VERSION ""

NS_ :

BS_:

BU_: DBG VCU BMS MCM DCU

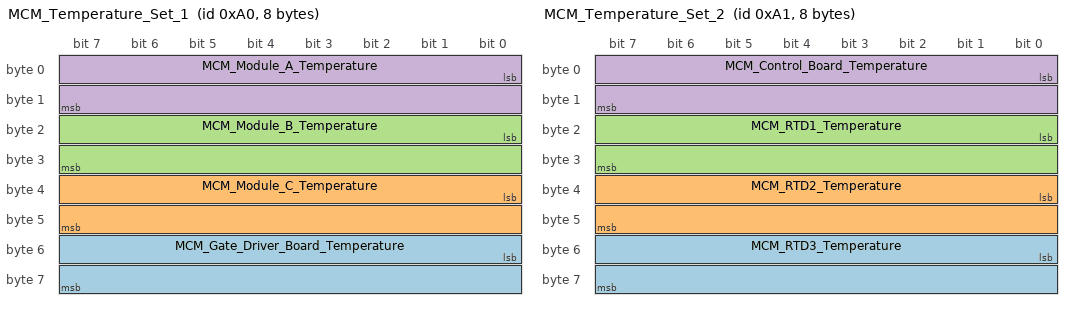
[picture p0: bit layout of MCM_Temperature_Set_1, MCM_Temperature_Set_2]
BO_ 160 MCM_Temperature_Set_1: 8 MCM
 SG_ MCM_Gate_Driver_Board_Temperature : 48|16@1- (0.1,0) [-3276.8|3276.7] "C" VCU
 SG_ MCM_Module_C_Temperature : 32|16@1- (0.1,0) [-3276.8|3276.7] "C" VCU
 SG_ MCM_Module_B_Temperature : 16|16@1- (0.1,0) [-3276.8|3276.7] "C" VCU
 SG_ MCM_Module_A_Temperature : 0|16@1- (0.1,0) [-3276.8|3276.7] "C" VCU

BO_ 161 MCM_Temperature_Set_2: 8 MCM
 SG_ MCM_RTD3_Temperature : 48|16@1- (0.1,0) [-3276.8|3276.7] "C" VCU
 SG_ MCM_RTD2_Temperature : 32|16@1- (0.1,0) [-3276.8|3276.7] "C" VCU
 SG_ MCM_RTD1_Temperature : 16|16@1- (0.1,0) [-3276.8|3276.7] "C" VCU
 SG_ MCM_Control_Board_Temperature : 0|16@1- (0.1,0) [-3276.8|3276.7] "C" VCU

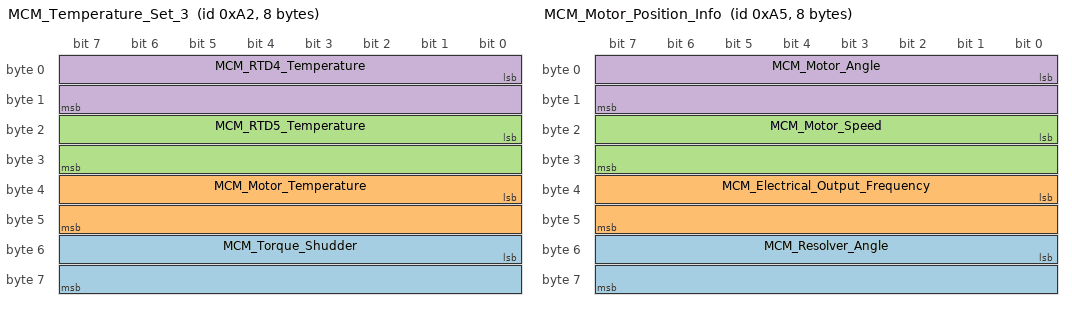
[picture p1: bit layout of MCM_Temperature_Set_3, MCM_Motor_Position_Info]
BO_ 162 MCM_Temperature_Set_3: 8 MCM
 SG_ MCM_Torque_Shudder : 48|16@1- (0.1,0) [-3276.8|3276.7] "Nm" VCU
 SG_ MCM_Motor_Temperature : 32|16@1- (0.1,0) [-3276.8|3276.7] "C" VCU
 SG_ MCM_RTD5_Temperature : 16|16@1- (0.1,0) [-3276.8|3276.7] "C" VCU
 SG_ MCM_RTD4_Temperature : 0|16@1- (0.1,0) [-3276.8|3276.7] "C" VCU

BO_ 165 MCM_Motor_Position_Info: 8 MCM
 SG_ MCM_Resolver_Angle : 48|16@1- (0.1,0) [-3276.8|3276.7] "DEG" VCU
 SG_ MCM_Electrical_Output_Frequency : 32|16@1- (0.1,0) [-3276.8|3276.7] "Hz" VCU
 SG_ MCM_Motor_Speed : 16|16@1- (1,0) [-32768|32767] "RPM" VCU
 SG_ MCM_Motor_Angle : 0|16@1+ (0.1,0) [0|6553.5] "DEG" VCU

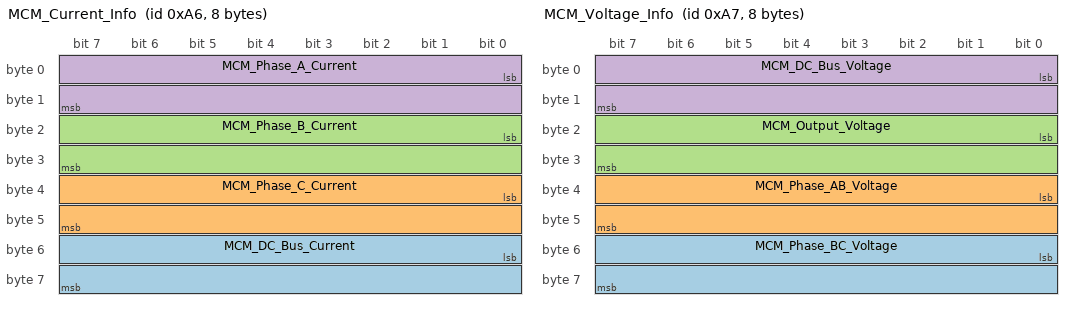
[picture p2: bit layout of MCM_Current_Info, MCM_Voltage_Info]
BO_ 166 MCM_Current_Info: 8 MCM
 SG_ MCM_DC_Bus_Current : 48|16@1- (0.1,0) [-3276.8|3276.7] "A" VCU
 SG_ MCM_Phase_C_Current : 32|16@1- (0.1,0) [-3276.8|3276.7] "A" VCU
 SG_ MCM_Phase_B_Current : 16|16@1- (0.1,0) [-3276.8|3276.7] "A" VCU
 SG_ MCM_Phase_A_Current : 0|16@1- (0.1,0) [-3276.8|3276.7] "A" VCU

BO_ 167 MCM_Voltage_Info: 8 MCM
 SG_ MCM_Phase_BC_Voltage : 48|16@1- (0.1,0) [-3276.8|3276.7] "V" VCU
 SG_ MCM_Phase_AB_Voltage : 32|16@1- (0.1,0) [-3276.8|3276.7] "V" VCU
 SG_ MCM_Output_Voltage : 16|16@1- (0.1,0) [-3276.8|3276.7] "V" VCU
 SG_ MCM_DC_Bus_Voltage : 0|16@1- (0.1,0) [-3276.8|3276.7] "V" VCU

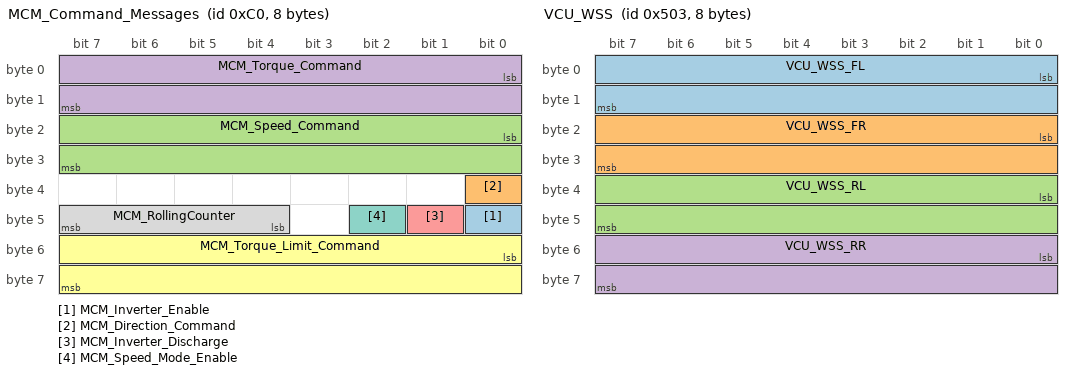
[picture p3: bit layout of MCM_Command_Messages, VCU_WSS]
BO_ 192 MCM_Command_Messages: 8 VCU
 SG_ MCM_Inverter_Enable : 40|1@1+ (1,0) [0|1] "Bit" MCM
 SG_ MCM_Direction_Command : 32|1@1+ (1,0) [0|1] "Bit" MCM
 SG_ MCM_Speed_Command : 16|16@1- (1,0) [-32768|32767] "rpm" MCM
 SG_ MCM_Torque_Command : 0|16@1- (0.1,0) [-3276.8|3276.7] "Nm" MCM
 SG_ MCM_Inverter_Discharge : 41|1@1+ (1,0) [0|1] "Bit" MCM
 SG_ MCM_Torque_Limit_Command : 48|16@1- (0.1,0) [-3276.8|3276.7] "Nm" MCM
 SG_ MCM_Speed_Mode_Enable : 42|1@1+ (1,0) [0|1] "Bit" MCM
 SG_ MCM_RollingCounter : 44|4@1+ (1,0) [0|15] "Bits" MCM

BO_ 1280 VCU_TPS0: 8 VCU
 SG_ VCU_TPS0_Value : 16|16@1+ (0.0946969697,-714) [0|100] "%" VCU

BO_ 1281 VCU_TPS1: 8 VCU
 SG_ VCU_TPS1_Value : 16|16@1+ (0.0916590284,-3563) [0|100] "%" VCU

BO_ 1282 VCU_BPS: 8 VCU
 SG_ VCU_BPS_Percent : 0|16@1+ (1,0) [0|100] "%" VCU
 SG_ VCU_BPS_Value : 16|16@1+ (0.1,0) [0|8000] "PSI" VCU

BO_ 1283 VCU_WSS: 8 VCU
 SG_ VCU_WSS_FL : 0|16@1- (1,0) [-100000|100000] "mm/s" VCU
 SG_ VCU_WSS_FR : 16|16@1- (1,0) [-100000|100000] "mm/s" VCU
 SG_ VCU_WSS_RL : 32|16@1- (1,0) [-100000|100000] "mm/s" VCU
 SG_ VCU_WSS_RR : 48|16@1- (1,0) [-100000|100000] "mm/s" VCU

BO_ 1286 VCU_Safety_Checker: 8 VCU
 SG_ VCU_FAULT_TPS_OutOfRange : 0|1@1+ (1,0) [0|1] "Bit" VCU
 SG_ VCU_FAULT_BPS_OutOfRange : 1|1@1+ (1,0) [0|1] "Bit" VCU
 SG_ VCU_FAULT_TPS_PowerFailure : 2|1@1+ (1,0) [0|1] "Bit" VCU
 SG_ VCU_FAULT_BPS_PowerFailure : 3|1@1+ (1,0) [0|1] "Bit" VCU
 SG_ VCU_FAULT_TPS_SignalFailure : 4|1@1+ (1,0) [0|1] "Bit" VCU
 SG_ VCU_FAULT_BPS_SignalFailure : 5|1@1+ (1,0) [0|1] "Bit" VCU
 SG_ VCU_FAULT_TPS_NotCalibrated : 6|1@1+ (1,0) [0|1] "Bit" VCU
 SG_ VCU_FAULT_BPS_NotCalibrated : 7|1@1+ (1,0) [0|1] "Bit" VCU
 SG_ VCU_FAULT_TPS_OutOfSync : 8|1@1+ (1,0) [0|1] "Bit" VCU
 SG_ VCU_FAULT_BPS_OutOfSync : 9|1@1+ (1,0) [0|1] "Bit" VCU
 SG_ VCU_FAULT_TPSBPS_Implausible : 10|1@1+ (1,0) [0|1] "Bit" VCU
 SG_ VCU_FAULT_UNUSED_11 : 11|1@1+ (1,0) [0|1] "Bit" VCU
 SG_ VCU_FAULT_UNUSED_12 : 12|1@1+ (1,0) [0|1] "Bit" VCU
 SG_ VCU_FAULT_UNUSED_13 : 13|1@1+ (1,0) [0|1] "Bit" VCU
 SG_ VCU_FAULT_UNUSED_14 : 14|1@1+ (1,0) [0|1] "Bit" VCU
 SG_ VCU_FAULT_UNUSED_15 : 15|1@1+ (1,0) [0|1] "Bit" VCU
 SG_ VCU_FAULT_LVS_BatteryVeryLow : 16|1@1+ (1,0) [0|1] "Bit" VCU
 SG_ VCU_FAULT_UNUSED_17 : 17|1@1+ (1,0) [0|1] "Bit" VCU
 SG_ VCU_FAULT_UNUSED_18 : 18|1@1+ (1,0) [0|1] "Bit" VCU
 SG_ VCU_FAULT_UNUSED_19 : 19|1@1+ (1,0) [0|1] "Bit" VCU
 SG_ VCU_FAULT_UNUSED_20 : 20|1@1+ (1,0) [0|1] "Bit" VCU
 SG_ VCU_FAULT_UNUSED_21 : 21|1@1+ (1,0) [0|1] "Bit" VCU
 SG_ VCU_FAULT_UNUSED_22 : 22|1@1+ (1,0) [0|1] "Bit" VCU
 SG_ VCU_FAULT_UNUSED_23 : 23|1@1+ (1,0) [0|1] "Bit" VCU
 SG_ VCU_FAULT_UNUSED_24 : 24|1@1+ (1,0) [0|1] "Bit" VCU
 SG_ VCU_FAULT_UNUSED_25 : 25|1@1+ (1,0) [0|1] "Bit" VCU
 SG_ VCU_FAULT_UNUSED_26 : 26|1@1+ (1,0) [0|1] "Bit" VCU
 SG_ VCU_FAULT_UNUSED_27 : 27|1@1+ (1,0) [0|1] "Bit" VCU
 SG_ VCU_FAULT_UNUSED_28 : 28|1@1+ (1,0) [0|1] "Bit" VCU
 SG_ VCU_FAULT_UNUSED_29 : 29|1@1+ (1,0) [0|1] "Bit" VCU
 SG_ VCU_FAULT_UNUSED_30 : 30|1@1+ (1,0) [0|1] "Bit" VCU
 SG_ VCU_FAULT_UNUSED_31 : 31|1@1+ (1,0) [0|1] "Bit" VCU
 SG_ VCU_WARNING_LVS_BatteryLow : 32|1@1+ (1,0) [0|1] "Bit" VCU
 SG_ VCU_WARNING_UNUSED_33 : 33|1@1+ (1,0) [0|1] "Bit" VCU
 SG_ VCU_WARNING_UNUSED_34 : 34|1@1+ (1,0) [0|1] "Bit" VCU
 SG_ VCU_WARNING_UNUSED_35 : 35|1@1+ (1,0) [0|1] "Bit" VCU
 SG_ VCU_WARNING_UNUSED_36 : 36|1@1+ (1,0) [0|1] "Bit" VCU
 SG_ VCU_WARNING_UNUSED_37 : 37|1@1+ (1,0) [0|1] "Bit" VCU
 SG_ VCU_WARNING_HVIL_OverrideEnabled: 38|1@1+ (1,0) [0|1] "Bit" VCU
 SG_ VCU_WARNING_SAFETY_BypassEnabled : 39|1@1+ (1,0) [0|1] "Bit" VCU
 SG_ VCU_WARNING_UNUSED_40 : 40|1@1+ (1,0) [0|1] "Bit" VCU
 SG_ VCU_WARNING_UNUSED_41 : 41|1@1+ (1,0) [0|1] "Bit" VCU
 SG_ VCU_WARNING_UNUSED_42 : 42|1@1+ (1,0) [0|1] "Bit" VCU
 SG_ VCU_WARNING_UNUSED_43 : 43|1@1+ (1,0) [0|1] "Bit" VCU
 SG_ VCU_WARNING_UNUSED_44 : 44|1@1+ (1,0) [0|1] "Bit" VCU
 SG_ VCU_WARNING_UNUSED_45 : 45|1@1+ (1,0) [0|1] "Bit" VCU
 SG_ VCU_WARNING_UNUSED_46 : 46|1@1+ (1,0) [0|1] "Bit" VCU
 SG_ VCU_WARNING_UNUSED_47 : 47|1@1+ (1,0) [0|1] "Bit" VCU
 SG_ VCU_NOTICE_HVIL_TermSenseLost : 48|1@1+ (1,0) [0|1] "Bit" VCU
 SG_ VCU_NOTICE_UNUSED_49 : 49|1@1+ (1,0) [0|1] "Bit" VCU
 SG_ VCU_NOTICE_UNUSED_50 : 50|1@1+ (1,0) [0|1] "Bit" VCU
 SG_ VCU_NOTICE_UNUSED_51 : 51|1@1+ (1,0) [0|1] "Bit" VCU
 SG_ VCU_NOTICE_BMS_Over75kW : 52|1@1+ (1,0) [0|1] "Bit" VCU
 SG_ VCU_NOTICE_MCM_Over75kW : 53|1@1+ (1,0) [0|1] "Bit" VCU
 SG_ VCU_NOTICE_UNUSED_54 : 54|1@1+ (1,0) [0|1] "Bit" VCU
 SG_ VCU_NOTICE_UNUSED_55 : 55|1@1+ (1,0) [0|1] "Bit" VCU
 SG_ VCU_NOTICE_UNUSED_56 : 56|1@1+ (1,0) [0|1] "Bit" VCU
 SG_ VCU_NOTICE_UNUSED_57 : 57|1@1+ (1,0) [0|1] "Bit" VCU
 SG_ VCU_NOTICE_UNUSED_58 : 58|1@1+ (1,0) [0|1] "Bit" VCU
 SG_ VCU_NOTICE_UNUSED_59 : 59|1@1+ (1,0) [0|1] "Bit" VCU
 SG_ VCU_NOTICE_UNUSED_60 : 60|1@1+ (1,0) [0|1] "Bit" VCU
 SG_ VCU_NOTICE_UNUSED_61 : 61|1@1+ (1,0) [0|1] "Bit" VCU
 SG_ VCU_NOTICE_UNUSED_62 : 62|1@1+ (1,0) [0|1] "Bit" VCU
 SG_ VCU_NOTICE_UNUSED_63 : 63|1@1+ (1,0) [0|1] "Bit" VCU

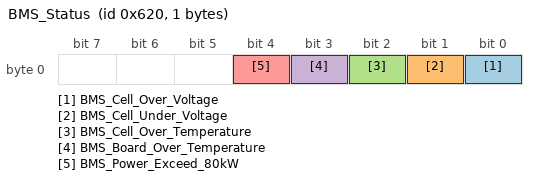
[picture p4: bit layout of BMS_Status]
BO_ 1568 BMS_Status: 1 BMS
 SG_ BMS_Cell_Over_Voltage : 0|1@1+ (1,0) [0|0] "Bit" VCU
 SG_ BMS_Cell_Under_Voltage : 1|1@1+ (1,0) [0|0] "Bit" VCU
 SG_ BMS_Cell_Over_Temperature : 2|1@1+ (1,0) [0|0] "Bit" VCU
 SG_ BMS_Board_Over_Temperature : 3|1@1+ (1,0) [0|0] "Bit" VCU
 SG_ BMS_Power_Exceed_80kW : 4|1@1+ (1,0) [0|0] "Bit" VCU

BO_ 1571 BMS_Pack_Info: 8 BMS
 SG_ BMS_Pack_Voltage : 0|32@1- (0.01,0) [0|300.0] "V" VCU
 SG_ BMS_Pack_Current : 32|32@1- (0.1,-3000) [-3000.0|3000.0] "A" VCU

BO_ 1572 BMS_Load_Info: 8 BMS
 SG_ BMS_Load_Voltage : 0|32@1- (0.01,0) [0|300.0] "V" VCU
 SG_ BMS_Load_Current : 32|32@1- (0.01,-3000) [-3000.0|3000.0] "A" VCU

BO_ 1573 BMS_Cell_Voltage_High_Low: 8 BMS
 SG_ BMS_Cell_Voltage_High : 0|32@1- (0.01,0) [0|6.55] "V" VCU
 SG_ BMS_Cell_Voltage_Low : 32|32@1- (0.01,0) [0|6.55] "V" VCU

BO_ 1574 BMS_Cell_Voltage_Average: 8 BMS
 SG_ BMS_Cell_Voltage_Average : 0|32@1- (0.01,0) [0|6.55] "V" VCU
 SG_ BMS_Cell_Voltage_Mismatch : 32|32@1- (0.01,0) [0|6.55] "V" VCU

BO_ 1575 BMS_Status_SoC: 8 BMS
 SG_ BMS_SOC : 0|32@1- (0.1,0) [0|100] "%" VCU
 SG_ BMS_Capacity : 32|32@1- (0.1,0) [0|30] "Ah" VCU

BO_ 1576 BMS_Temperature_Average: 8 BMS
 SG_ BMS_Cell_Temperature_Average : 0|32@1- (0.1,0) [-100.0|100.0] "C" VCU
 SG_ BMS_Board_Temperature_Average : 32|32@1- (0.1,0) [-100.0|100.0] "C" VCU

BO_ 1577 BMS_Cell_Temperature: 8 BMS
 SG_ BMS_Cell_Temperature_High : 0|32@1- (0.1,0) [-99.9|99.9] "C" VCU
 SG_ BMS_Cell_Temperature_Low : 32|32@1- (0.1,0) [-99.9|99.9] "C" VCU

BO_ 1584 BMS_Board_Temperature: 8 BMS
 SG_ BMS_Board_Temperature_High : 0|32@1- (0.1,0) [-100.0|100.0] "C" VCU
 SG_ BMS_Board_Temperature_Low : 32|32@1- (0.1,0) [-100.0|100.0] "C" VCU

BO_ 1585 BMS_Load_Power: 4 BMS
 SG_ BMS_Load_Power : 0|32@1- (0.1,0) [-79999.9|79999.9] "W" VCU

BO_ 1793 DCU_Timestamp: 1 DCU
 SG_ DCU_Timestamp : 0|8@1+ (1,0) [0|255] "" VCU

CM_ BU_ VCU "The vehicle control unit";
CM_ BU_ MCM "The motor controller of the car";
CM_ BU_ BMS "The battery management system";
CM_ BU_ DCU "The dash control unit";
CM_ BO_ 160 "Motor Controller Temperatures Set 1";
CM_ BO_ 161 "Motor Controller Temperatures Set 2";
CM_ BO_ 162 "Motor Controller Temperatures Set 3";
CM_ BO_ 165 "Motor Position Information";
CM_ BO_ 166 "Motor Current Information";
CM_ BO_ 167 "Motor Voltage Information";
CM_ BO_ 192 "Motor Controller Command Messages";
CM_ BO_ 1280 "Throttle Position Sensor 0 Value";
CM_ BO_ 1281 "Throttle Position Sensor 1 Value";
CM_ BO_ 1282 "Brake Pressure Sensor Value";
CM_ BO_ 1283 "Wheel Speed Sensor Value";
CM_ BO_ 1286 "VCU Safety Messages";
CM_ BO_ 1568 "BMS Status and Fault Message";
CM_ BO_ 1571 "Accumulator Pack Voltage and Current";
CM_ BO_ 1572 "Accumulator Load Voltage and Current";
CM_ BO_ 1573 "Cell Voltage High and Low";
CM_ BO_ 1574 "Cell Voltage Average and Mismatch";
CM_ BO_ 1575 "SOC Percentage and Battery Capacity";
CM_ BO_ 1576 "Cell and BMS Board Temperature Average";
CM_ BO_ 1577 "Cell Temperature High and Low";
CM_ BO_ 1584 "BMS Board Temperature High and Low";
CM_ BO_ 1585 "Accumulator Load Power";
CM_ BO_ 1793 "Dash Control Unit Timestamp";

BA_DEF_ "BusType" STRING ;
BA_DEF_ SG_ "FieldType" STRING ;

BA_DEF_DEF_ "BusType" "CAN";
BA_DEF_DEF_ "FieldType" "";

BA_ "FieldType" SG_ 100 DRIVER_HEARTBEAT_cmd "DRIVER_HEARTBEAT_cmd";

VAL_ 100 DRIVER_HEARTBEAT_cmd 2 "DRIVER_HEARTBEAT_cmd_REBOOT" 1 "DRIVER_HEARTBEAT_cmd_SYNC" 0 "DRIVER_HEARTBEAT_cmd_NOOP" ;
